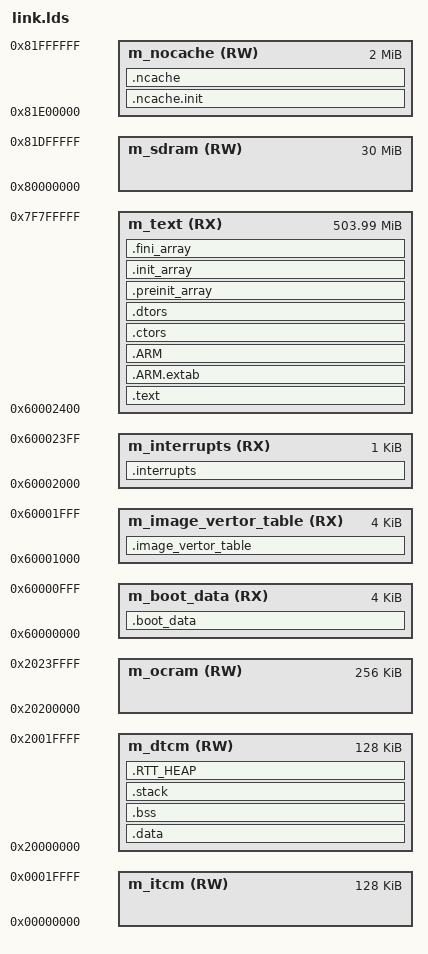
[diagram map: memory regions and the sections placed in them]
/*
** ###################################################################
**     Processors:          MIMXRT1052CVL5A
**                          MIMXRT1052DVL6A
**
**     Compiler:            GNU C Compiler
**     Reference manual:    IMXRT1050RM Rev.C, 08/2017
**     Version:             rev. 0.1, 2017-01-10
**     Build:               b170927
**
**     Abstract:
**         Linker file for the GNU C Compiler
**
**     Copyright 2016 Freescale Semiconductor, Inc.
**     Copyright 2016-2017 NXP
**     Redistribution and use in source and binary forms, with or without modification,
**     are permitted provided that the following conditions are met:
**
**     1. Redistributions of source code must retain the above copyright notice, this list
**       of conditions and the following disclaimer.
**
**     2. Redistributions in binary form must reproduce the above copyright notice, this
**       list of conditions and the following disclaimer in the documentation and/or
**       other materials provided with the distribution.
**
**     3. Neither the name of the copyright holder nor the names of its
**       contributors may be used to endorse or promote products derived from this
**       software without specific prior written permission.
**
**     THIS SOFTWARE IS PROVIDED BY THE COPYRIGHT HOLDERS AND CONTRIBUTORS "AS IS" AND
**     ANY EXPRESS OR IMPLIED WARRANTIES, INCLUDING, BUT NOT LIMITED TO, THE IMPLIED
**     WARRANTIES OF MERCHANTABILITY AND FITNESS FOR A PARTICULAR PURPOSE ARE
**     DISCLAIMED. IN NO EVENT SHALL THE COPYRIGHT HOLDER OR CONTRIBUTORS BE LIABLE FOR
**     ANY DIRECT, INDIRECT, INCIDENTAL, SPECIAL, EXEMPLARY, OR CONSEQUENTIAL DAMAGES
**     (INCLUDING, BUT NOT LIMITED TO, PROCUREMENT OF SUBSTITUTE GOODS OR SERVICES;
**     LOSS OF USE, DATA, OR PROFITS; OR BUSINESS INTERRUPTION) HOWEVER CAUSED AND ON
**     ANY THEORY OF LIABILITY, WHETHER IN CONTRACT, STRICT LIABILITY, OR TORT
**     (INCLUDING NEGLIGENCE OR OTHERWISE) ARISING IN ANY WAY OUT OF THE USE OF THIS
**     SOFTWARE, EVEN IF ADVISED OF THE POSSIBILITY OF SUCH DAMAGE.
**
**     http:                 www.nxp.com
**     mail:                 support@nxp.com
**
** ###################################################################
*/

/* Entry Point */
ENTRY(Reset_Handler)

HEAP_SIZE  = DEFINED(__heap_size__)  ? __heap_size__  : 0x0400;
STACK_SIZE = DEFINED(__stack_size__) ? __stack_size__ : 0x0400;

/* Specify the memory areas */
MEMORY
{
  m_boot_data           (RX)  : ORIGIN = 0x60000000, LENGTH = 0x00001000
  m_image_vertor_table  (RX)  : ORIGIN = 0x60001000, LENGTH = 0x00001000

  m_interrupts          (RX)  : ORIGIN = 0x60002000, LENGTH = 0x00000400
  m_text                (RX)  : ORIGIN = 0x60002400, LENGTH = 0x1F7FDC00

  m_itcm                (RW)  : ORIGIN = 0x00000000, LENGTH = 0x00020000
  m_dtcm                (RW)  : ORIGIN = 0x20000000, LENGTH = 0x00020000
  m_ocram               (RW)  : ORIGIN = 0x20200000, LENGTH = 0x00040000

  m_sdram               (RW)  : ORIGIN = 0x80000000, LENGTH = 0x01E00000
  m_nocache             (RW)  : ORIGIN = 0x81E00000, LENGTH = 0x00200000
}

/* Define output sections */
SECTIONS
{
  .boot_data :
  {
    KEEP(*(.boot_hdr.conf))
  } > m_boot_data

  .image_vertor_table :
  {
    KEEP(*(.boot_hdr.ivt))
    KEEP(*(.boot_hdr.boot_data))
    KEEP(*(.boot_hdr.dcd_data))
  } > m_image_vertor_table

  /* The startup code goes first into internal RAM */
  .interrupts :
  {
    __VECTOR_TABLE = .;
    . = ALIGN(4);
    KEEP(*(.isr_vector))     /* Startup code */
    . = ALIGN(4);
  } > m_interrupts

  __VECTOR_RAM = __VECTOR_TABLE;
  __RAM_VECTOR_TABLE_SIZE_BYTES = 0x0;

  /* The program code and other data goes into internal RAM */
  .text :
  {
    . = ALIGN(4);
    *(.text)                 /* .text sections (code) */
    *(.text*)                /* .text* sections (code) */
    *(.rodata)               /* .rodata sections (constants, strings, etc.) */
    *(.rodata*)              /* .rodata* sections (constants, strings, etc.) */
    *(.glue_7)               /* glue arm to thumb code */
    *(.glue_7t)              /* glue thumb to arm code */
    *(.eh_frame)
    KEEP (*(.init))
    KEEP (*(.fini))
    . = ALIGN(4);

    /* section information for finsh shell */
    . = ALIGN(4);
    __fsymtab_start = .;
    KEEP(*(FSymTab))
    __fsymtab_end = .;
    . = ALIGN(4);
    __vsymtab_start = .;
    KEEP(*(VSymTab))
    __vsymtab_end = .;
    . = ALIGN(4);

    /* section information for initial. */
    . = ALIGN(4);
    __rt_init_start = .;
    KEEP(*(SORT(.rti_fn*)))
    __rt_init_end = .;
  } > m_text

  .ARM.extab :
  {
    *(.ARM.extab* .gnu.linkonce.armextab.*)
  } > m_text

  .ARM :
  {
    __exidx_start = .;
    *(.ARM.exidx*)
    __exidx_end = .;
  } > m_text

 .ctors :
  {
    PROVIDE(__ctors_start__ = .);
    /* __CTOR_LIST__ = .; */
    /* gcc uses crtbegin.o to find the start of
       the constructors, so we make sure it is
       first.  Because this is a wildcard, it
       doesn't matter if the user does not
       actually link against crtbegin.o; the
       linker won't look for a file to match a
       wildcard.  The wildcard also means that it
       doesn't matter which directory crtbegin.o
       is in.  */
    KEEP (*crtbegin.o(.ctors))
    KEEP (*crtbegin?.o(.ctors))
    /* We don't want to include the .ctor section from
       from the crtend.o file until after the sorted ctors.
       The .ctor section from the crtend file contains the
       end of ctors marker and it must be last */
    KEEP (*(EXCLUDE_FILE(*crtend?.o *crtend.o) .ctors))
    KEEP (*(SORT(.ctors.*)))
    KEEP (*(.ctors))
    /* __CTOR_END__ = .; */
    PROVIDE(__ctors_end__ = .);
  } > m_text

  .dtors :
  {
    PROVIDE(__dtors_start__ = .);
    /* __DTOR_LIST__ = .; */
    KEEP (*crtbegin.o(.dtors))
    KEEP (*crtbegin?.o(.dtors))
    KEEP (*(EXCLUDE_FILE(*crtend?.o *crtend.o) .dtors))
    KEEP (*(SORT(.dtors.*)))
    KEEP (*(.dtors))
    /* __DTOR_END__ = .; */
    PROVIDE(__dtors_end__ = .);
  } > m_text

  .preinit_array :
  {
    PROVIDE_HIDDEN (__preinit_array_start = .);
    KEEP (*(.preinit_array*))
    PROVIDE_HIDDEN (__preinit_array_end = .);
  } > m_text

  .init_array :
  {
    PROVIDE_HIDDEN (__init_array_start = .);
    KEEP (*(SORT(.init_array.*)))
    KEEP (*(.init_array*))
    PROVIDE_HIDDEN (__init_array_end = .);
  } > m_text

  .fini_array :
  {
    PROVIDE_HIDDEN (__fini_array_start = .);
    KEEP (*(SORT(.fini_array.*)))
    KEEP (*(.fini_array*))
    PROVIDE_HIDDEN (__fini_array_end = .);
  } > m_text

  __etext = .;    /* define a global symbol at end of code */
  __DATA_ROM = .; /* Symbol is used by startup for data initialization */

  .data : AT(__DATA_ROM)
  {
    . = ALIGN(4);
    __DATA_RAM = .;
    __data_start__ = .;      /* create a global symbol at data start */
    *(m_usb_dma_init_data)
    *(.data)                 /* .data sections */
    *(.data*)                /* .data* sections */
    KEEP(*(.jcr*))
    . = ALIGN(4);
    __data_end__ = .;        /* define a global symbol at data end */
  } > m_dtcm

  __NDATA_ROM = __DATA_ROM + (__data_end__ - __data_start__);
  .ncache.init : AT(__NDATA_ROM)
  {
    __noncachedata_start__ = .;   /* create a global symbol at ncache data start */
    *(NonCacheable.init)
    . = ALIGN(4);
    __noncachedata_init_end__ = .;   /* create a global symbol at initialized ncache data end */
  } > m_nocache
  . = __noncachedata_init_end__;
  .ncache :
  {
    *(NonCacheable)
    . = ALIGN(4);
    __noncachedata_end__ = .;     /* define a global symbol at ncache data end */
  } > m_nocache

  __DATA_END = __NDATA_ROM + (__noncachedata_init_end__ - __noncachedata_start__);
  text_end = ORIGIN(m_text) + LENGTH(m_text);
  ASSERT(__DATA_END <= text_end, "region m_text overflowed with text and data")

  /* Uninitialized data section */
  .bss :
  {
    /* This is used by the startup in order to initialize the .bss section */
    . = ALIGN(4);
    __START_BSS = .;
    __bss_start__ = .;
    *(m_usb_dma_noninit_data)
    *(.bss)
    *(.bss*)
    *(COMMON)
    . = ALIGN(4);
    __bss_end__ = .;
    __END_BSS = .;
  } > m_dtcm

  .stack :
  {
    . = ALIGN(8);
    stack_start = .;
    . += STACK_SIZE;
    stack_end = .;
    __StackTop = .;
  } > m_dtcm

  .RTT_HEAP :
  {
    heap_start = .;
    . = ALIGN(8);
  } > m_dtcm

  PROVIDE(heap_end = ORIGIN(m_dtcm) + LENGTH(m_dtcm));

  .ARM.attributes 0 : { *(.ARM.attributes) }

}

